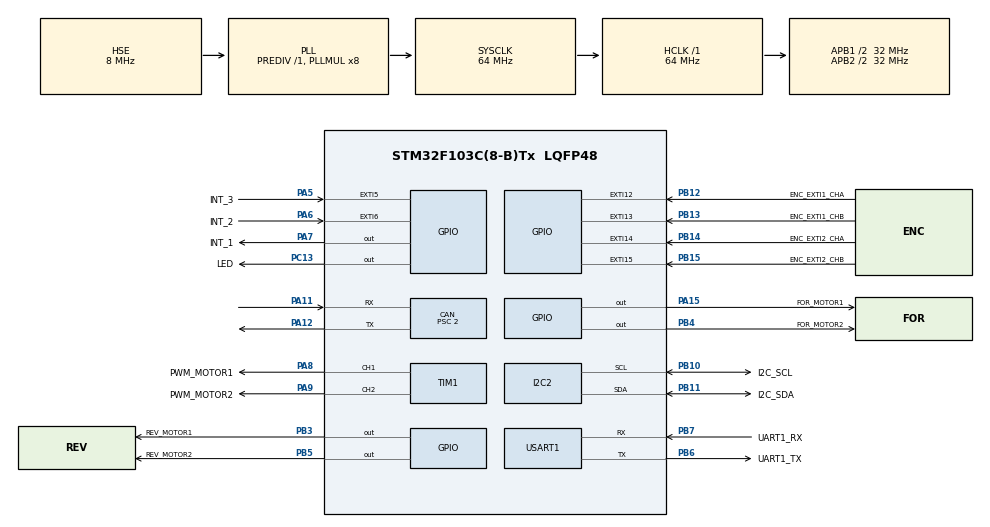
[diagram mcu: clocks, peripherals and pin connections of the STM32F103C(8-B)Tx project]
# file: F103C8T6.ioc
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CAN.BS1=CAN_BS1_13TQ
CAN.BS2=CAN_BS2_2TQ
CAN.CalculateBaudRate=1000000
CAN.CalculateTimeBit=1000
CAN.CalculateTimeQuantum=62.5
CAN.Prescaler=2
Dma.Request0=USART1_RX
Dma.Request1=USART1_TX
Dma.USART1_RX.0.Direction=DMA_PERIPH_TO_MEMORY
Dma.USART1_RX.0.Instance=DMA1_Channel5
Dma.USART1_RX.0.MemDataAlignment=DMA_MDATAALIGN_BYTE
Dma.USART1_RX.0.MemInc=DMA_MINC_ENABLE
Dma.USART1_RX.0.Mode=DMA_CIRCULAR
Dma.USART1_RX.0.PeriphDataAlignment=DMA_PDATAALIGN_BYTE
Dma.USART1_RX.0.PeriphInc=DMA_PINC_DISABLE
Dma.USART1_RX.0.Priority=DMA_PRIORITY_VERY_HIGH
Dma.USART1_TX.1.Direction=DMA_MEMORY_TO_PERIPH
Dma.USART1_TX.1.Instance=DMA1_Channel4
Dma.USART1_TX.1.MemDataAlignment=DMA_MDATAALIGN_BYTE
Dma.USART1_TX.1.MemInc=DMA_MINC_ENABLE
Dma.USART1_TX.1.Mode=DMA_NORMAL
Dma.USART1_TX.1.PeriphDataAlignment=DMA_PDATAALIGN_BYTE
Dma.USART1_TX.1.PeriphInc=DMA_PINC_DISABLE
Dma.USART1_TX.1.Priority=DMA_PRIORITY_VERY_HIGH
Mcu.Family=STM32F1
Mcu.Name=STM32F103C(8-B)Tx
Mcu.Package=LQFP48
NVIC.CAN1_RX1_IRQn=true\:0\:0\:false\:false\:true\:true\:true\:true
NVIC.DMA1_Channel4_IRQn=true\:0\:0\:false\:false\:true\:false\:true\:true
NVIC.DMA1_Channel5_IRQn=true\:0\:0\:false\:false\:true\:false\:true\:true
NVIC.EXTI15_10_IRQn=true\:0\:0\:false\:false\:true\:true\:true\:true
NVIC.EXTI9_5_IRQn=true\:0\:0\:false\:false\:true\:true\:true\:true
NVIC.PriorityGroup=NVIC_PRIORITYGROUP_4
NVIC.TIM2_IRQn=true\:0\:0\:false\:false\:true\:true\:true\:true
NVIC.TIM4_IRQn=true\:15\:0\:false\:false\:true\:false\:true\:true
NVIC.TimeBase=TIM4_IRQn
NVIC.TimeBaseIP=TIM4
NVIC.USART1_IRQn=true\:0\:0\:false\:false\:true\:true\:true\:true
PA11.GPIO_PuPd=GPIO_PULLUP
PA11.Mode=CAN_Activate
PA11.Signal=CAN_RX
PA12.Mode=CAN_Activate
PA12.Signal=CAN_TX
PA13.Mode=Serial_Wire
PA13.Signal=SYS_JTMS-SWDIO
PA14.Mode=Serial_Wire
PA14.Signal=SYS_JTCK-SWCLK
PA15.GPIO_Label=FOR_MOTOR1
PA15.Signal=GPIO_Output
PA5.GPIO_Label=INT_3
PA5.GPIO_ModeDefaultEXTI=GPIO_MODE_IT_FALLING
PA5.GPIO_PuPd=GPIO_PULLUP
PA5.Signal=GPXTI5
PA6.GPIO_Label=INT_2
PA6.GPIO_ModeDefaultEXTI=GPIO_MODE_IT_FALLING
PA6.GPIO_PuPd=GPIO_PULLUP
PA6.Signal=GPXTI6
PA7.GPIO_Label=INT_1
PA7.Signal=GPIO_Output
PA8.GPIO_Label=PWM_MOTOR1
PA8.Signal=S_TIM1_CH1
PA9.GPIO_Label=PWM_MOTOR2
PA9.Signal=S_TIM1_CH2
PB10.GPIO_Label=I2C_SCL
PB10.Mode=I2C
PB10.Signal=I2C2_SCL
PB11.GPIO_Label=I2C_SDA
PB11.Mode=I2C
PB11.Signal=I2C2_SDA
PB12.GPIO_Label=ENC_EXTI1_CHA
PB12.GPIO_ModeDefaultEXTI=GPIO_MODE_IT_RISING_FALLING
PB12.Signal=GPXTI12
PB13.GPIO_Label=ENC_EXTI1_CHB
PB13.GPIO_ModeDefaultEXTI=GPIO_MODE_IT_RISING_FALLING
PB13.Signal=GPXTI13
PB14.GPIO_Label=ENC_EXTI2_CHA
PB14.GPIO_ModeDefaultEXTI=GPIO_MODE_IT_RISING_FALLING
PB14.Signal=GPXTI14
PB15.GPIO_Label=ENC_EXTI2_CHB
PB15.GPIO_ModeDefaultEXTI=GPIO_MODE_IT_RISING_FALLING
PB15.Signal=GPXTI15
PB3.GPIO_Label=REV_MOTOR1
PB3.Signal=GPIO_Output
PB4.GPIO_Label=FOR_MOTOR2
PB4.Signal=GPIO_Output
PB5.GPIO_Label=REV_MOTOR2
PB5.Signal=GPIO_Output
PB6.GPIO_Label=UART1_TX
PB6.Mode=Asynchronous
PB6.Signal=USART1_TX
PB7.GPIO_Label=UART1_RX
PB7.Mode=Asynchronous
PB7.Signal=USART1_RX
PC13-TAMPER-RTC.GPIO_Label=LED
PC13-TAMPER-RTC.Signal=GPIO_Output
PD0-OSC_IN.Mode=HSE-External-Oscillator
PD0-OSC_IN.Signal=RCC_OSC_IN
PD1-OSC_OUT.Mode=HSE-External-Oscillator
PD1-OSC_OUT.Signal=RCC_OSC_OUT
ProjectManager.HeapSize=0x200
ProjectManager.StackSize=0x400
ProjectManager.TargetToolchain=Makefile
RCC.AHBFreq_Value=64000000
RCC.APB1CLKDivider=RCC_HCLK_DIV2
RCC.APB1Freq_Value=32000000
RCC.APB1TimFreq_Value=64000000
RCC.APB2CLKDivider=RCC_HCLK_DIV2
RCC.APB2Freq_Value=32000000
RCC.APB2TimFreq_Value=64000000
RCC.HCLKFreq_Value=64000000
RCC.PLLMUL=RCC_PLL_MUL8
RCC.PLLSourceVirtual=RCC_PLLSOURCE_HSE
RCC.SYSCLKFreq_VALUE=64000000
RCC.SYSCLKSource=RCC_SYSCLKSOURCE_PLLCLK
RCC.USBFreq_Value=64000000
SH.S_TIM1_CH1.0=TIM1_CH1,PWM Generation1 CH1
SH.S_TIM1_CH2.0=TIM1_CH2,PWM Generation2 CH2
TIM1.Channel-PWM\ Generation1\ CH1=TIM_CHANNEL_1
TIM1.Channel-PWM\ Generation2\ CH2=TIM_CHANNEL_2
TIM2.Period=0xffff-1
TIM2.Prescaler=64-1
USART1.VirtualMode=VM_ASYNC
VP_SYS_VS_tim4.Mode=TIM4
VP_TIM2_VS_ClockSourceINT.Mode=Internal
board=custom

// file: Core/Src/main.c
/* USER CODE BEGIN Header */
/**
  ******************************************************************************
  * @file           : main.c
  * @brief          : Main program body
  ******************************************************************************
  * @attention
  *
  * Copyright (c) 2025 STMicroelectronics.
  * All rights reserved.
  *
  * This software is licensed under terms that can be found in the LICENSE file
  * in the root directory of this software component.
  * If no LICENSE file comes with this software, it is provided AS-IS.
  *
  ******************************************************************************
  */
/* USER CODE END Header */
#include "main.h"
#include "can.h"
#include "dma.h"
#include "i2c.h"
#include "tim.h"
#include "usart.h"
#include "gpio.h"

void SystemClock_Config(void);
/* USER CODE BEGIN PFP */
int main_app(void);
/* USER CODE END PFP */

int main(void)
{

  /* MCU Configuration--------------------------------------------------------*/

  /* Reset of all peripherals, Initializes the Flash interface and the Systick. */
  HAL_Init();

  /* Configure the system clock */
  SystemClock_Config();

  /* Initialize all configured peripherals */
  MX_GPIO_Init();
  MX_DMA_Init();
  MX_TIM1_Init();
  MX_CAN_Init();
  MX_USART1_UART_Init();
  MX_I2C2_Init();
  MX_TIM2_Init();
  /* USER CODE BEGIN 2 */
  main_app();
  /* USER CODE END 2 */

  /* Infinite loop */
  while (1)
  {

  }
}

void SystemClock_Config(void)
{
  RCC_OscInitTypeDef RCC_OscInitStruct = {0};
  RCC_ClkInitTypeDef RCC_ClkInitStruct = {0};

  /** Initializes the RCC Oscillators according to the specified parameters
  * in the RCC_OscInitTypeDef structure.
  */
  RCC_OscInitStruct.OscillatorType = RCC_OSCILLATORTYPE_HSE;
  RCC_OscInitStruct.HSEState = RCC_HSE_ON;
  RCC_OscInitStruct.HSEPredivValue = RCC_HSE_PREDIV_DIV1;
  RCC_OscInitStruct.HSIState = RCC_HSI_ON;
  RCC_OscInitStruct.PLL.PLLState = RCC_PLL_ON;
  RCC_OscInitStruct.PLL.PLLSource = RCC_PLLSOURCE_HSE;
  RCC_OscInitStruct.PLL.PLLMUL = RCC_PLL_MUL8;
  if (HAL_RCC_OscConfig(&RCC_OscInitStruct) != HAL_OK)
  {
    Error_Handler();
  }

  /** Initializes the CPU, AHB and APB buses clocks
  */
  RCC_ClkInitStruct.ClockType = RCC_CLOCKTYPE_HCLK|RCC_CLOCKTYPE_SYSCLK
                              |RCC_CLOCKTYPE_PCLK1|RCC_CLOCKTYPE_PCLK2;
  RCC_ClkInitStruct.SYSCLKSource = RCC_SYSCLKSOURCE_PLLCLK;
  RCC_ClkInitStruct.AHBCLKDivider = RCC_SYSCLK_DIV1;
  RCC_ClkInitStruct.APB1CLKDivider = RCC_HCLK_DIV2;
  RCC_ClkInitStruct.APB2CLKDivider = RCC_HCLK_DIV2;

  if (HAL_RCC_ClockConfig(&RCC_ClkInitStruct, FLASH_LATENCY_2) != HAL_OK)
  {
    Error_Handler();
  }
}

// void HAL_TIM_PeriodElapsedCallback(TIM_HandleTypeDef *htim)
// {
//   /* USER CODE BEGIN Callback 0 */

//   /* USER CODE END Callback 0 */
//   if (htim->Instance == TIM4) {
//     HAL_IncTick();
//   }
//   /* USER CODE BEGIN Callback 1 */

//   /* USER CODE END Callback 1 */
// }

void Error_Handler(void)
{
  __disable_irq();
  while (1)
  {
  }
}
